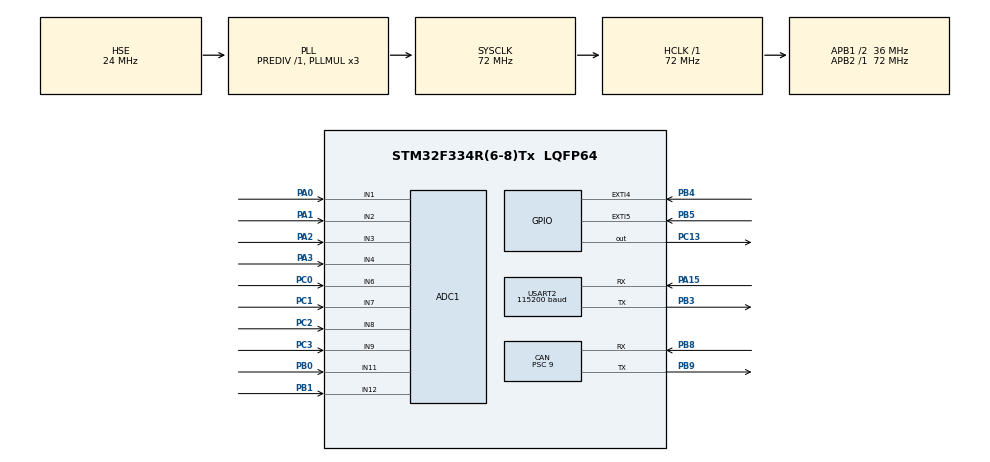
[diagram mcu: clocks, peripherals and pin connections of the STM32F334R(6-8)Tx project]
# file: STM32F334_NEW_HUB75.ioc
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ADC1.Channel-0\#ChannelRegularConversion=ADC_CHANNEL_1
ADC1.Channel-1\#ChannelRegularConversion=ADC_CHANNEL_2
ADC1.Channel-2\#ChannelRegularConversion=ADC_CHANNEL_3
ADC1.Channel-3\#ChannelRegularConversion=ADC_CHANNEL_4
ADC1.Channel-4\#ChannelRegularConversion=ADC_CHANNEL_6
ADC1.Channel-5\#ChannelRegularConversion=ADC_CHANNEL_7
ADC1.Channel-6\#ChannelRegularConversion=ADC_CHANNEL_8
ADC1.Channel-7\#ChannelRegularConversion=ADC_CHANNEL_9
ADC1.Channel-8\#ChannelRegularConversion=ADC_CHANNEL_11
ADC1.Channel-9\#ChannelRegularConversion=ADC_CHANNEL_12
ADC1.ContinuousConvMode=ENABLE
ADC1.DMAContinuousRequests=ENABLE
ADC1.NbrOfConversion=10
ADC1.NbrOfConversionFlag=1
ADC1.Offset-0\#ChannelRegularConversion=0
ADC1.Offset-1\#ChannelRegularConversion=0
ADC1.Offset-2\#ChannelRegularConversion=0
ADC1.Offset-3\#ChannelRegularConversion=0
ADC1.Offset-4\#ChannelRegularConversion=0
ADC1.Offset-5\#ChannelRegularConversion=0
ADC1.Offset-6\#ChannelRegularConversion=0
ADC1.Offset-7\#ChannelRegularConversion=0
ADC1.Offset-8\#ChannelRegularConversion=0
ADC1.Offset-9\#ChannelRegularConversion=0
ADC1.OffsetNumber-0\#ChannelRegularConversion=ADC_OFFSET_NONE
ADC1.OffsetNumber-1\#ChannelRegularConversion=ADC_OFFSET_NONE
ADC1.OffsetNumber-2\#ChannelRegularConversion=ADC_OFFSET_NONE
ADC1.OffsetNumber-3\#ChannelRegularConversion=ADC_OFFSET_NONE
ADC1.OffsetNumber-4\#ChannelRegularConversion=ADC_OFFSET_NONE
ADC1.OffsetNumber-5\#ChannelRegularConversion=ADC_OFFSET_NONE
ADC1.OffsetNumber-6\#ChannelRegularConversion=ADC_OFFSET_NONE
ADC1.OffsetNumber-7\#ChannelRegularConversion=ADC_OFFSET_NONE
ADC1.OffsetNumber-8\#ChannelRegularConversion=ADC_OFFSET_NONE
ADC1.OffsetNumber-9\#ChannelRegularConversion=ADC_OFFSET_NONE
ADC1.Rank-0\#ChannelRegularConversion=1
ADC1.Rank-1\#ChannelRegularConversion=2
ADC1.Rank-2\#ChannelRegularConversion=3
ADC1.Rank-3\#ChannelRegularConversion=4
ADC1.Rank-4\#ChannelRegularConversion=5
ADC1.Rank-5\#ChannelRegularConversion=6
ADC1.Rank-6\#ChannelRegularConversion=7
ADC1.Rank-7\#ChannelRegularConversion=8
ADC1.Rank-8\#ChannelRegularConversion=9
ADC1.Rank-9\#ChannelRegularConversion=10
ADC1.SamplingTime-0\#ChannelRegularConversion=ADC_SAMPLETIME_1CYCLE_5
ADC1.SamplingTime-1\#ChannelRegularConversion=ADC_SAMPLETIME_1CYCLE_5
ADC1.SamplingTime-2\#ChannelRegularConversion=ADC_SAMPLETIME_1CYCLE_5
ADC1.SamplingTime-3\#ChannelRegularConversion=ADC_SAMPLETIME_1CYCLE_5
ADC1.SamplingTime-4\#ChannelRegularConversion=ADC_SAMPLETIME_1CYCLE_5
ADC1.SamplingTime-5\#ChannelRegularConversion=ADC_SAMPLETIME_1CYCLE_5
ADC1.SamplingTime-6\#ChannelRegularConversion=ADC_SAMPLETIME_1CYCLE_5
ADC1.SamplingTime-7\#ChannelRegularConversion=ADC_SAMPLETIME_1CYCLE_5
ADC1.SamplingTime-8\#ChannelRegularConversion=ADC_SAMPLETIME_1CYCLE_5
ADC1.SamplingTime-9\#ChannelRegularConversion=ADC_SAMPLETIME_1CYCLE_5
ADC1.SamplingTimeOPAMP-1\#ChannelRegularConversion=ADC_SAMPLETIME_61CYCLES_5
ADC1.SamplingTimeOPAMP-2\#ChannelRegularConversion=ADC_SAMPLETIME_61CYCLES_5
ADC1.SamplingTimeOPAMP-3\#ChannelRegularConversion=ADC_SAMPLETIME_61CYCLES_5
ADC1.SamplingTimeOPAMP-4\#ChannelRegularConversion=ADC_SAMPLETIME_61CYCLES_5
ADC1.SamplingTimeOPAMP-5\#ChannelRegularConversion=ADC_SAMPLETIME_61CYCLES_5
ADC1.SamplingTimeOPAMP-6\#ChannelRegularConversion=ADC_SAMPLETIME_61CYCLES_5
ADC1.SamplingTimeOPAMP-7\#ChannelRegularConversion=ADC_SAMPLETIME_61CYCLES_5
ADC1.SamplingTimeOPAMP-8\#ChannelRegularConversion=ADC_SAMPLETIME_61CYCLES_5
ADC1.SamplingTimeOPAMP-9\#ChannelRegularConversion=ADC_SAMPLETIME_61CYCLES_5
ADC1.SubFamily=STM32F334x8
ADC1.master=1
CAN.BS1=CAN_BS1_2TQ
CAN.CalculateBaudRate=1000000
CAN.CalculateTimeBit=1000
CAN.CalculateTimeQuantum=250.0
CAN.Prescaler=9
Dma.ADC1.0.Direction=DMA_PERIPH_TO_MEMORY
Dma.ADC1.0.Instance=DMA1_Channel1
Dma.ADC1.0.MemDataAlignment=DMA_MDATAALIGN_HALFWORD
Dma.ADC1.0.MemInc=DMA_MINC_ENABLE
Dma.ADC1.0.Mode=DMA_CIRCULAR
Dma.ADC1.0.PeriphDataAlignment=DMA_PDATAALIGN_HALFWORD
Dma.ADC1.0.PeriphInc=DMA_PINC_DISABLE
Dma.ADC1.0.Priority=DMA_PRIORITY_MEDIUM
Dma.Request0=ADC1
Mcu.Family=STM32F3
Mcu.Name=STM32F334R(6-8)Tx
Mcu.Package=LQFP64
NVIC.ADC1_2_IRQn=true\:1\:0\:true\:false\:true\:true\:true\:true
NVIC.CAN_RX0_IRQn=true\:0\:0\:false\:false\:true\:true\:true\:true
NVIC.CAN_RX1_IRQn=true\:0\:0\:false\:false\:true\:true\:true\:true
NVIC.DMA1_Channel1_IRQn=true\:0\:0\:false\:false\:true\:false\:true\:true
NVIC.EXTI4_IRQn=true\:0\:0\:false\:false\:true\:true\:true\:true
NVIC.EXTI9_5_IRQn=true\:0\:0\:false\:false\:true\:true\:true\:true
NVIC.PriorityGroup=NVIC_PRIORITYGROUP_4
NVIC.TIM2_IRQn=true\:0\:0\:false\:false\:true\:true\:true\:true
PA0.Mode=IN1-Single-Ended
PA0.Signal=ADC1_IN1
PA1.Mode=IN2-Single-Ended
PA1.Signal=ADC1_IN2
PA13.Mode=Serial_Wire
PA13.Signal=SYS_JTMS-SWDIO
PA14.Mode=Serial_Wire
PA14.Signal=SYS_JTCK-SWCLK
PA15.Mode=Asynchronous
PA15.Signal=USART2_RX
PA2.Mode=IN3-Single-Ended
PA2.Signal=ADC1_IN3
PA3.Mode=IN4-Single-Ended
PA3.Signal=ADC1_IN4
PB0.Mode=IN11-Single-Ended
PB0.Signal=ADC1_IN11
PB1.Mode=IN12-Single-Ended
PB1.Signal=ADC1_IN12
PB3.Mode=Asynchronous
PB3.Signal=USART2_TX
PB4.GPIO_ModeDefaultEXTI=GPIO_MODE_IT_FALLING
PB4.Signal=GPXTI4
PB5.GPIO_ModeDefaultEXTI=GPIO_MODE_IT_FALLING
PB5.Signal=GPXTI5
PB8.Mode=CAN_Activate
PB8.Signal=CAN_RX
PB9.Mode=CAN_Activate
PB9.Signal=CAN_TX
PC0.Signal=ADCx_IN6
PC1.Signal=ADCx_IN7
PC13.GPIO_ModeDefaultOutputPP=GPIO_MODE_OUTPUT_OD
PC13.GPIO_PuPd=GPIO_NOPULL
PC13.Signal=GPIO_Output
PC2.Signal=ADCx_IN8
PC3.Signal=ADCx_IN9
PF0\ /\ OSC_IN.Mode=HSE-External-Oscillator
PF0\ /\ OSC_IN.Signal=RCC_OSC_IN
PF1\ /\ OSC_OUT.Mode=HSE-External-Oscillator
PF1\ /\ OSC_OUT.Signal=RCC_OSC_OUT
ProjectManager.HeapSize=0x200
ProjectManager.StackSize=0x400
ProjectManager.TargetToolchain=CMake
RCC.ADC12PRES=RCC_ADC12PLLCLK_DIV6
RCC.AHBFreq_Value=72000000
RCC.APB1CLKDivider=RCC_HCLK_DIV2
RCC.APB1Freq_Value=36000000
RCC.APB1TimFreq_Value=72000000
RCC.APB2Freq_Value=72000000
RCC.APB2TimFreq_Value=72000000
RCC.CortexFreq_Value=72000000
RCC.HCLKFreq_Value=72000000
RCC.HSE_VALUE=24000000
RCC.HSI_VALUE=8000000
RCC.LSE_VALUE=32768
RCC.PLLMUL=RCC_PLL_MUL3
RCC.PLLSourceVirtual=RCC_PLLSOURCE_HSE
RCC.SYSCLKFreq_VALUE=72000000
RCC.SYSCLKSourceVirtual=RCC_SYSCLKSOURCE_PLLCLK
SH.ADCx_IN6.0=ADC1_IN6,IN6-Single-Ended
SH.ADCx_IN7.0=ADC1_IN7,IN7-Single-Ended
SH.ADCx_IN8.0=ADC1_IN8,IN8-Single-Ended
SH.ADCx_IN9.0=ADC1_IN9,IN9-Single-Ended
TIM2.Period=1000-1
TIM2.Prescaler=72-1
USART2.BaudRate=115200
USART2.VirtualMode-Asynchronous=VM_ASYNC
VP_TIM2_VS_ClockSourceINT.Mode=Internal
board=custom

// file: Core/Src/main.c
/* USER CODE BEGIN Header */
/**
  ******************************************************************************
  * @file           : main.c
  * @brief          : Main program body
  ******************************************************************************
  * @attention
  *
  * Copyright (c) 2026 STMicroelectronics.
  * All rights reserved.
  *
  * This software is licensed under terms that can be found in the LICENSE file
  * in the root directory of this software component.
  * If no LICENSE file comes with this software, it is provided AS-IS.
  *
  ******************************************************************************
  */
/* USER CODE END Header */
#include "main.h"
#include "adc.h"
#include "can.h"
#include "dma.h"
#include "tim.h"
#include "usart.h"
#include "gpio.h"

/* USER CODE BEGIN Includes */
#include "app.h"
/* USER CODE END Includes */

void SystemClock_Config(void);

int main(void)
{

  /* MCU Configuration--------------------------------------------------------*/

  /* Reset of all peripherals, Initializes the Flash interface and the Systick. */
  HAL_Init();

  /* Configure the system clock */
  SystemClock_Config();

  /* Initialize all configured peripherals */
  MX_GPIO_Init();
  MX_DMA_Init();
  MX_ADC1_Init();
  MX_CAN_Init();
  MX_TIM2_Init();
  MX_USART2_UART_Init();
  /* USER CODE BEGIN 2 */
  App_Init();
  /* USER CODE END 2 */

  /* Infinite loop */
  while (1)
  {

  }
}

void SystemClock_Config(void)
{
  RCC_OscInitTypeDef RCC_OscInitStruct = {0};
  RCC_ClkInitTypeDef RCC_ClkInitStruct = {0};
  RCC_PeriphCLKInitTypeDef PeriphClkInit = {0};

  /** Initializes the RCC Oscillators according to the specified parameters
  * in the RCC_OscInitTypeDef structure.
  */
  RCC_OscInitStruct.OscillatorType = RCC_OSCILLATORTYPE_HSE;
  RCC_OscInitStruct.HSEState = RCC_HSE_ON;
  RCC_OscInitStruct.HSEPredivValue = RCC_HSE_PREDIV_DIV1;
  RCC_OscInitStruct.HSIState = RCC_HSI_ON;
  RCC_OscInitStruct.PLL.PLLState = RCC_PLL_ON;
  RCC_OscInitStruct.PLL.PLLSource = RCC_PLLSOURCE_HSE;
  RCC_OscInitStruct.PLL.PLLMUL = RCC_PLL_MUL3;
  if (HAL_RCC_OscConfig(&RCC_OscInitStruct) != HAL_OK)
  {
    Error_Handler();
  }

  /** Initializes the CPU, AHB and APB buses clocks
  */
  RCC_ClkInitStruct.ClockType = RCC_CLOCKTYPE_HCLK|RCC_CLOCKTYPE_SYSCLK
                              |RCC_CLOCKTYPE_PCLK1|RCC_CLOCKTYPE_PCLK2;
  RCC_ClkInitStruct.SYSCLKSource = RCC_SYSCLKSOURCE_PLLCLK;
  RCC_ClkInitStruct.AHBCLKDivider = RCC_SYSCLK_DIV1;
  RCC_ClkInitStruct.APB1CLKDivider = RCC_HCLK_DIV2;
  RCC_ClkInitStruct.APB2CLKDivider = RCC_HCLK_DIV1;

  if (HAL_RCC_ClockConfig(&RCC_ClkInitStruct, FLASH_LATENCY_2) != HAL_OK)
  {
    Error_Handler();
  }
  PeriphClkInit.PeriphClockSelection = RCC_PERIPHCLK_ADC12;
  PeriphClkInit.Adc12ClockSelection = RCC_ADC12PLLCLK_DIV6;
  if (HAL_RCCEx_PeriphCLKConfig(&PeriphClkInit) != HAL_OK)
  {
    Error_Handler();
  }
}

void Error_Handler(void)
{
  __disable_irq();
  while (1)
  {
  }
}
